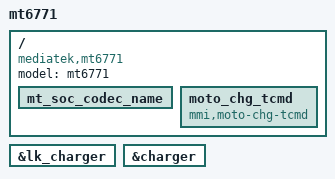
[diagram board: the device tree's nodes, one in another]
/*
 * MT6771 Bingo main dts override
 * Things can done here:
 * 	Add nodes or properties to root node
 * 	Delete nodes or properties
*/
/ {
	model = "mt6771";
	compatible = "mediatek,mt6771";

	mt_soc_codec_name: mt_soc_codec_name {
	};

	moto_chg_tcmd: moto_chg_tcmd {
		compatible = "mmi,moto-chg-tcmd";
	};
};
&lk_charger {
	/delete-property/ enable_pe_plus;
};
&charger {
	/delete-property/ enable_pe_plus;
	/delete-property/ enable_pe_2;
	/delete-property/ enable_pe_3;
	/delete-property/ enable_pe_4;
	/delete-property/ enable_type_c;
};
